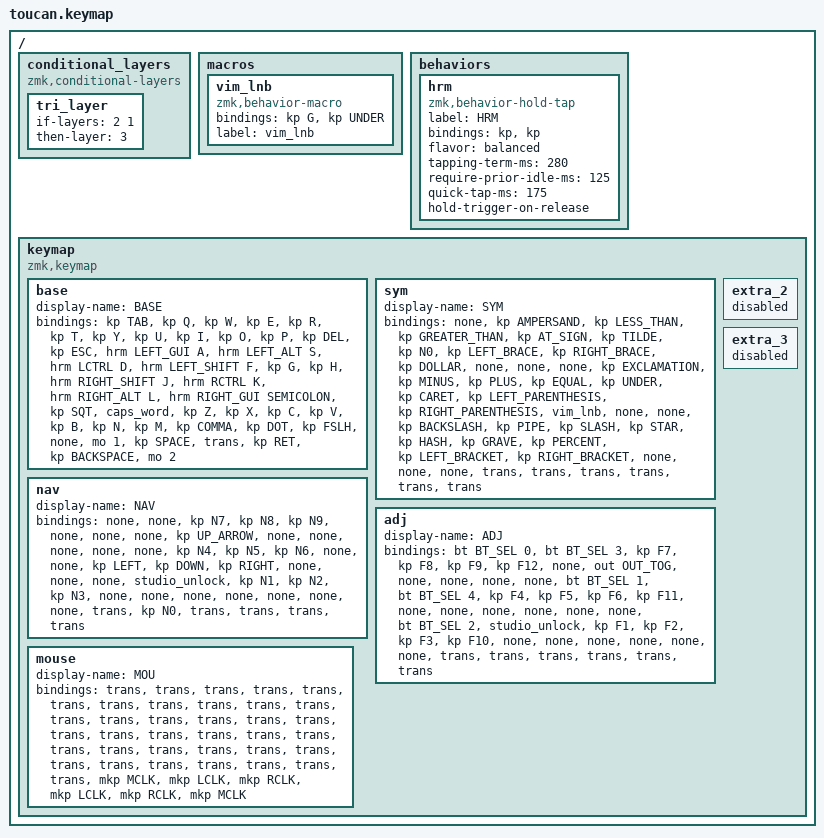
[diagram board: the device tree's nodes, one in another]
#include <behaviors.dtsi>
#include <dt-bindings/zmk/bt.h>
#include <dt-bindings/zmk/keys.h>
#include <dt-bindings/zmk/outputs.h>
#include <dt-bindings/zmk/pointing.h>

#define BASE 0
#define NAV  1
#define SYM  2
#define ADJ  3

/ {
    conditional_layers {
        compatible = "zmk,conditional-layers";

        tri_layer {
            if-layers = <2 1>;
            then-layer = <3>;
        };
    };

    macros {
        vim_lnb: vim_lnb {
            compatible = "zmk,behavior-macro";
            #binding-cells = <0>;
            bindings = <&kp G &kp UNDER>;
            label = "vim_lnb";
        };
    };

    behaviors {
        hrm: hrm {
            compatible = "zmk,behavior-hold-tap";
            label = "HRM";
            bindings = <&kp>, <&kp>;

            #binding-cells = <2>;
            flavor = "balanced";
            tapping-term-ms = <280>;
            require-prior-idle-ms = <125>;
            quick-tap-ms = <175>;
            hold-trigger-on-release;
        };
    };

    keymap {
        compatible = "zmk,keymap";

        base {
            display-name = "BASE";
            bindings = <
&kp TAB  &kp Q  &kp W  &kp E  &kp R  &kp T  &kp Y  &kp U  &kp I  &kp O  &kp P  &kp DEL  &kp ESC  &hrm LEFT_GUI A  &hrm LEFT_ALT S  &hrm LCTRL D  &hrm LEFT_SHIFT F  &kp G  &kp H  &hrm RIGHT_SHIFT J  &hrm RCTRL K  &hrm RIGHT_ALT L  &hrm RIGHT_GUI SEMICOLON  &kp SQT  &caps_word  &kp Z  &kp X  &kp C  &kp V  &kp B  &kp N  &kp M  &kp COMMA  &kp DOT  &kp FSLH  &none  &mo 1  &kp SPACE  &trans  &kp RET  &kp BACKSPACE  &mo 2
            >;
        };

        sym {
            display-name = "SYM";
            bindings = <
&none  &kp AMPERSAND  &kp LESS_THAN  &kp GREATER_THAN  &kp AT_SIGN  &kp TILDE  &kp N0  &kp LEFT_BRACE  &kp RIGHT_BRACE  &kp DOLLAR  &none  &none  &none  &kp EXCLAMATION  &kp MINUS  &kp PLUS  &kp EQUAL  &kp UNDER  &kp CARET  &kp LEFT_PARENTHESIS  &kp RIGHT_PARENTHESIS  &vim_lnb  &none  &none  &kp BACKSLASH  &kp PIPE  &kp SLASH  &kp STAR  &kp HASH  &kp GRAVE  &kp PERCENT  &kp LEFT_BRACKET  &kp RIGHT_BRACKET  &none  &none  &none  &trans  &trans  &trans  &trans  &trans  &trans
            >;
        };

        nav {
            display-name = "NAV";
            bindings = <
&none  &none  &kp N7  &kp N8  &kp N9  &none  &none  &none  &kp UP_ARROW  &none  &none  &none  &none  &none  &kp N4  &kp N5  &kp N6  &none  &none  &kp LEFT  &kp DOWN  &kp RIGHT  &none  &none  &none  &studio_unlock  &kp N1  &kp N2  &kp N3  &none  &none  &none  &none  &none  &none  &none  &trans  &kp N0  &trans  &trans  &trans  &trans
            >;
        };

        adj {
            display-name = "ADJ";
            bindings = <
&bt BT_SEL 0  &bt BT_SEL 3  &kp F7  &kp F8  &kp F9  &kp F12  &none  &out OUT_TOG  &none  &none  &none  &none  &bt BT_SEL 1  &bt BT_SEL 4  &kp F4  &kp F5  &kp F6  &kp F11  &none  &none  &none  &none  &none  &none  &bt BT_SEL 2  &studio_unlock  &kp F1  &kp F2  &kp F3  &kp F10  &none  &none  &none  &none  &none  &none  &trans  &trans  &trans  &trans  &trans  &trans
            >;
        };

        mouse {
            display-name = "MOU";
            bindings = <
&trans  &trans  &trans  &trans  &trans  &trans  &trans  &trans  &trans  &trans  &trans  &trans  &trans  &trans  &trans  &trans  &trans  &trans  &trans  &trans  &trans  &trans  &trans  &trans  &trans  &trans  &trans  &trans  &trans  &trans  &trans  &trans  &trans  &trans  &trans  &trans  &mkp MCLK  &mkp LCLK  &mkp RCLK  &mkp LCLK  &mkp RCLK  &mkp MCLK
            >;
        };

        extra_2 { status = "reserved"; };

        extra_3 { status = "reserved"; };
    };
};

